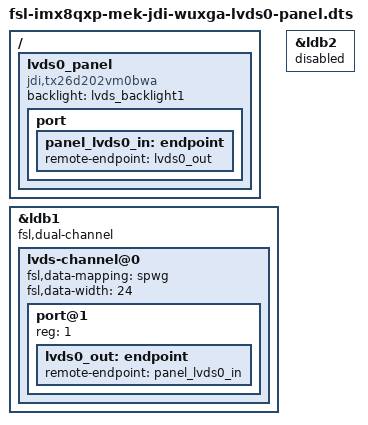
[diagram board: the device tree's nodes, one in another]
/*
 * Copyright 2018 NXP
 *
 * This program is free software; you can redistribute it and/or
 * modify it under the terms of the GNU General Public License
 * as published by the Free Software Foundation; either version 2
 * of the License, or (at your option) any later version.
 *
 * This program is distributed in the hope that it will be useful,
 * but WITHOUT ANY WARRANTY; without even the implied warranty of
 * MERCHANTABILITY or FITNESS FOR A PARTICULAR PURPOSE.  See the
 * GNU General Public License for more details.
 */

#include "fsl-imx8qxp-mek.dts"

/ {
	lvds0_panel {
		compatible = "jdi,tx26d202vm0bwa";
		backlight = <&lvds_backlight1>;

		port {
			panel_lvds0_in: endpoint {
				remote-endpoint = <&lvds0_out>;
			};
		};
	};
};

&ldb1 {
	fsl,dual-channel;

	lvds-channel@0 {
		fsl,data-mapping = "spwg";
		fsl,data-width = <24>;

		port@1 {
			reg = <1>;

			lvds0_out: endpoint {
				remote-endpoint = <&panel_lvds0_in>;
			};
		};
	};
};

&ldb2 {
	status = "disabled";
};
